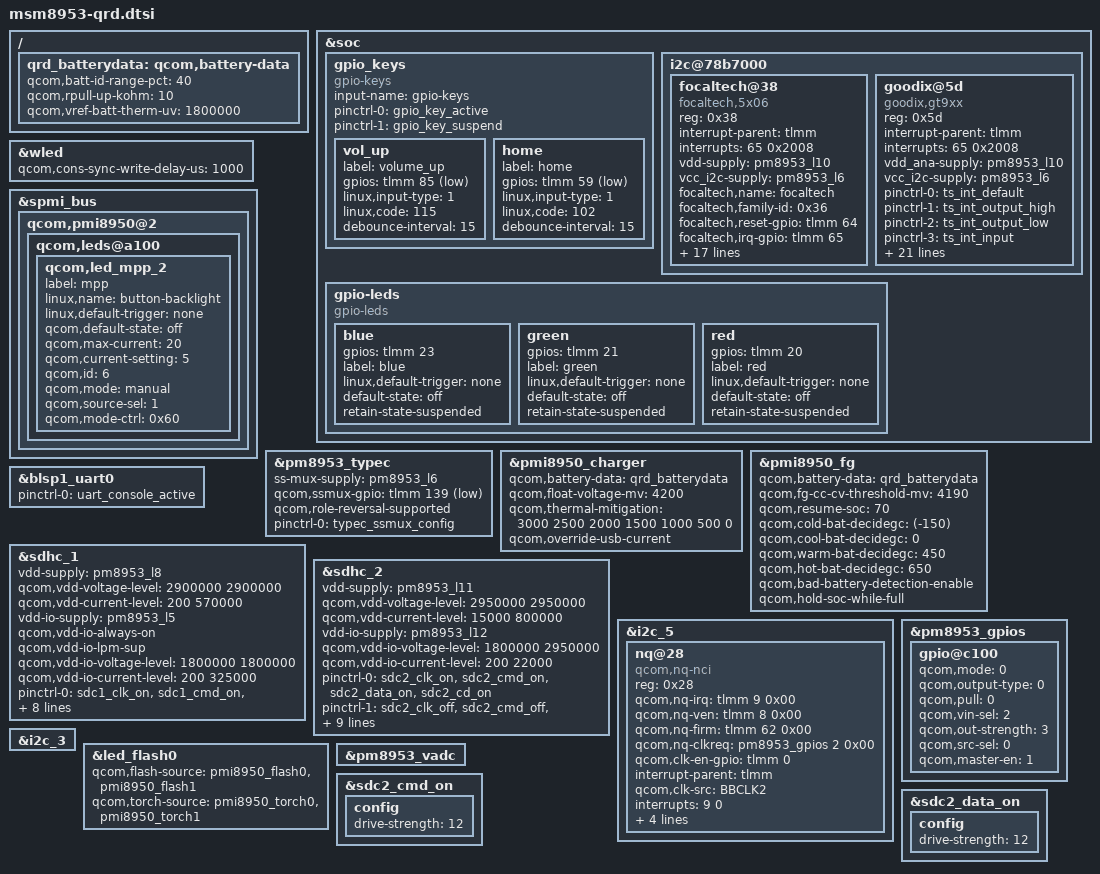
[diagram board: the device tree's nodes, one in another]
/*
 * Copyright (c) 2015-2016, The Linux Foundation. All rights reserved.
 *
 * This program is free software; you can redistribute it and/or modify
 * it under the terms of the GNU General Public License version 2 and
 * only version 2 as published by the Free Software Foundation.
 *
 * This program is distributed in the hope that it will be useful,
 * but WITHOUT ANY WARRANTY; without even the implied warranty of
 * MERCHANTABILITY or FITNESS FOR A PARTICULAR PURPOSE.  See the
 * GNU General Public License for more details.
 */

#include "msm8953-pinctrl.dtsi"
#include "msm8953-camera-sensor-qrd.dtsi"

&soc {
	gpio_keys {
		compatible = "gpio-keys";
		input-name = "gpio-keys";
		pinctrl-names = "tlmm_gpio_key_active","tlmm_gpio_key_suspend";
		pinctrl-0 = <&gpio_key_active>;
		pinctrl-1 = <&gpio_key_suspend>;

		vol_up {
			label = "volume_up";
			gpios = <&tlmm 85 0x1>;
			linux,input-type = <1>;
			linux,code = <115>;
			debounce-interval = <15>;
		};
		home {
			label = "home";
			gpios = <&tlmm 59 0x1>;
			linux,input-type = <1>;
			linux,code = <102>;
			debounce-interval = <15>;
		};
	};

	i2c@78b7000 { /* BLSP1 QUP3 */
		status = "okay";
		focaltech@38 {
			compatible = "focaltech,5x06";
			reg = <0x38>;
			interrupt-parent = <&tlmm>;
			interrupts = <65 0x2008>;
			vdd-supply = <&pm8953_l10>;
			vcc_i2c-supply = <&pm8953_l6>;
			/* pins used by touchscreen */
			focaltech,name = "focaltech";
			focaltech,family-id = <0x36>;
			focaltech,reset-gpio = <&tlmm 64 0x00>;
			focaltech,irq-gpio = <&tlmm 65 0x2008>;
			focaltech,display-coords = <0 0 800 1280>;
			focaltech,panel-coords = <0 0 800 1450>;
			focaltech,button-map= <139 102 158>;
			focaltech,no-force-update;
			focaltech,i2c-pull-up;
			focaltech,group-id = <1>;
			focaltech,hard-reset-delay-ms = <20>;
			focaltech,soft-reset-delay-ms = <200>;
			focaltech,num-max-touches = <5>;
			focaltech,fw-delay-aa-ms = <30>;
			focaltech,fw-delay-55-ms = <30>;
			focaltech,fw-upgrade-id1 = <0x79>;
			focaltech,fw-upgrade-id2 = <0x18>;
			focaltech,fw-delay-readid-ms = <10>;
			focaltech,fw-delay-era-flsh-ms = <2000>;
			focaltech,fw-auto-cal;
			focaltech,ignore-id-check;
		};
		goodix@5d {
			compatible = "goodix,gt9xx";
			reg = <0x5d>;
			interrupt-parent = <&tlmm>;
			interrupts = <65 0x2008>;
			vdd_ana-supply = <&pm8953_l10>;
			vcc_i2c-supply = <&pm8953_l6>;
			pinctrl-names = "default","int-output-high","int-output-low","int-input";
			pinctrl-0 = <&ts_int_default>;
			pinctrl-1 = <&ts_int_output_high>;
			pinctrl-2 = <&ts_int_output_low>;
			pinctrl-3 = <&ts_int_input>;
			reset-gpios = <&tlmm 64 0x00>;
			irq-gpios = <&tlmm 65 0x2008>;
			irq-flags = <2>;
			touchscreen-max-id = <11>;
			touchscreen-size-x = <800>;
			touchscreen-size-y = <1280>;
			touchscreen-max-w = <512>;
			touchscreen-max-p = <512>;
			touchscreen-key-map = <59>,<158>,<139>, <60>;
			goodix,slide-wakeup = <0>;
			goodix,type-a-report = <0>;
			goodix,driver-send-cfg = <0>;
			goodix,resume-in-workqueue = <0>;
			goodix,int-sync = <1>;
			goodix,swap-x2y = <0>;
			goodix,esd-protect = <1>;
			goodix,auto-update-cfg = <0>;
			goodix,power-off-sleep = <1>;	
			goodix,pen-suppress-finger = <0>;
			goodix,cfg-group0 = [00 20 03 00 05 0A 35 01 11 CF 28 0F 50 3C
			03 05 00 00 00 00 00 00 06 18 1A 1E 14 8C 2E 0E 55 57 D3 07 00
			00 00 02 02 1C 00 00 00 00 00 00 00 00 00 00 00 46 96 94 D5 02
			07 00 00 04 8B 4B 00 7D 58 00 72 66 00 69 77 00 62 8B 00 62 20
			18 10 08 F0 4A 3A FF FF 27 00 00 00 00 00 00 00 00 00 00 00 00
			00 00 00 00 00 00 00 00 00 00 00 00 00 00 02 04 06 08 0A 0C 0E
			10 12 14 16 18 1A 1C 00 00 00 00 00 00 00 00 00 00 00 00 00 00
			00 00 00 02 04 06 08 0A 0C 0F 10 12 13 14 18 1C 1D 1E 1F 20 21
			22 24 26 28 29 2A 16 00 00 00 00 00 00 00 00 00 00 00 00 00 00 00 00 08 01];
		};
	};
/* kun.chen rm
	vdd_vreg: vdd_vreg {
		compatible = "regulator-fixed";
		status = "ok";
		regulator-name = "vdd_vreg";
	};
*/
	gpio-leds {
		compatible = "gpio-leds";
		status = "okay";

		blue {
			gpios = <&tlmm 23 0x0>;
			label = "blue";
			linux,default-trigger = "none";
			default-state = "off";
			retain-state-suspended;
		};
		green {
			gpios = <&tlmm 21 0x0>;
			label = "green";
			linux,default-trigger = "none";
			default-state = "off";
			retain-state-suspended;
		};
		red {
			gpios = <&tlmm 20 0x0>;
			label = "red";
			linux,default-trigger = "none";
			default-state = "off";
			retain-state-suspended;
		};
	};
};

&wled {
	qcom,cons-sync-write-delay-us = <1000>;
};

&spmi_bus {
	qcom,pmi8950@2 {
		qcom,leds@a100 {
			status = "okay";
			qcom,led_mpp_2 {
				label = "mpp";
				linux,name = "button-backlight";
				linux,default-trigger = "none";
				qcom,default-state = "off";
				qcom,max-current = <20>;
				qcom,current-setting = <5>;
				qcom,id = <6>;
				qcom,mode = "manual";
				qcom,source-sel = <1>;
				qcom,mode-ctrl = <0x60>;
			};
		};
	};
};

/ {
	qrd_batterydata: qcom,battery-data {
		/*qcom,batt-id-range-pct = <15>;
		#include "batterydata-qrd-sku1-4v4-2800mah.dtsi"*/
		qcom,batt-id-range-pct = <40>;
		qcom,rpull-up-kohm = <10>;
		qcom,vref-batt-therm-uv = <1800000>;
		#include "batterydata-hwe30100100_2p-c801-4v2-6600mah_10k.dtsi"
		#include "batterydata-fullymax-fb382030xl-c801-4v2-135mah_20k.dtsi"
	};
};

&pm8953_typec {
	ss-mux-supply = <&pm8953_l6>;
	qcom,ssmux-gpio = <&tlmm 139 GPIO_ACTIVE_LOW>;
	qcom,role-reversal-supported;
	pinctrl-names = "default";
	pinctrl-0 = <&typec_ssmux_config>;
};

&pmi8950_charger {
	qcom,battery-data = <&qrd_batterydata>;
	qcom,float-voltage-mv = <4200>;
	/*qcom,chg-led-sw-controls;*/
	/*qcom,chg-led-support;*/
	/*qcom,external-typec;
	qcom,typec-psy-name = "typec";
	qcom,thermal-mitigation = <2650 2650 2650 2650 2600 700 0>;*/
	qcom,thermal-mitigation = <3000 2500 2000 1500 1000 500 0>;
	/*should be enabled after battery profile and charger testing*/
	qcom,override-usb-current;
	status = "okay";
};

&pmi8950_fg {
	qcom,battery-data = <&qrd_batterydata>;
	qcom,fg-cc-cv-threshold-mv = <4190>;
	qcom,resume-soc = <70>;
	qcom,cold-bat-decidegc = <(-150)>;
	qcom,cool-bat-decidegc = <0>;
	qcom,warm-bat-decidegc = <450>;
	qcom,hot-bat-decidegc = <650>;
	qcom,bad-battery-detection-enable;
	qcom,hold-soc-while-full;
};

&blsp1_uart0 {
	status = "ok";
	pinctrl-names = "default";
	pinctrl-0 = <&uart_console_active>;
};

&sdhc_1 {
	/* device core power supply */
	vdd-supply = <&pm8953_l8>;
	qcom,vdd-voltage-level = <2900000 2900000>;
	qcom,vdd-current-level = <200 570000>;

	/* device communication power supply */
	vdd-io-supply = <&pm8953_l5>;
	qcom,vdd-io-always-on;
	qcom,vdd-io-lpm-sup;
	qcom,vdd-io-voltage-level = <1800000 1800000>;
	qcom,vdd-io-current-level = <200 325000>;

	pinctrl-names = "active", "sleep";
	pinctrl-0 = <&sdc1_clk_on &sdc1_cmd_on &sdc1_data_on &sdc1_rclk_on>;
	pinctrl-1 = <&sdc1_clk_off &sdc1_cmd_off &sdc1_data_off &sdc1_rclk_off>;

	qcom,clk-rates = <400000 20000000 25000000 50000000 100000000 192000000
								384000000>;
	qcom,nonremovable;
	qcom,bus-speed-mode = "HS400_1p8v", "HS200_1p8v", "DDR_1p8v";

	status = "ok";
};

&sdhc_2 {
	/* device core power supply */
	vdd-supply = <&pm8953_l11>;
	qcom,vdd-voltage-level = <2950000 2950000>;
	qcom,vdd-current-level = <15000 800000>;

	/* device communication power supply */
	vdd-io-supply = <&pm8953_l12>;
	qcom,vdd-io-voltage-level = <1800000 2950000>;
	qcom,vdd-io-current-level = <200 22000>;

	pinctrl-names = "active", "sleep";
	pinctrl-0 = <&sdc2_clk_on &sdc2_cmd_on &sdc2_data_on &sdc2_cd_on>;
	pinctrl-1 = <&sdc2_clk_off &sdc2_cmd_off &sdc2_data_off &sdc2_cd_off>;

	#address-cells = <0>;
	interrupt-parent = <&sdhc_2>;
	interrupts = <0 1 2>;
	#interrupt-cells = <1>;
	interrupt-map-mask = <0xffffffff>;
	interrupt-map = <0 &intc 0 125 0
		1 &intc 0 221 0>;
	interrupt-names = "hc_irq", "pwr_irq", "status_irq";

	qcom,clk-rates = <400000 20000000 25000000 50000000 100000000
								200000000>;
	qcom,bus-speed-mode = "SDR12", "SDR25", "SDR50", "DDR50", "SDR104";

	status = "ok";
};

&i2c_5 { /* BLSP2 QUP1 (NFC) */
	nq@28 {
		    compatible = "qcom,nq-nci";
        	reg = <0x28>;
        	qcom,nq-irq = <&tlmm 9 0x00>;
        	qcom,nq-ven = <&tlmm 8 0x00>;
        	qcom,nq-firm = <&tlmm 62 0x00>;
        	qcom,nq-clkreq = <&pm8953_gpios 2 0x00>;
        	qcom,clk-en-gpio = <&tlmm 0 0x00>;
        	interrupt-parent = <&tlmm>;
        	qcom,clk-src = "BBCLK2";
        	interrupts = <9 0>;
        	interrupt-names = "nfc_irq";
        	pinctrl-names = "nfc_active", "nfc_suspend";
        	pinctrl-0 = <&nfc_int_active &nfc_disable_active>;
        	pinctrl-1 = <&nfc_int_suspend &nfc_disable_suspend>;
        	clocks = <&clock_gcc clk_bb_clk2_pin>;
        	clock-names = "ref_clk";
	};
};

&pm8953_gpios {
	/* GPIO 2 (NFC_CLK_REQ) */
	gpio@c100 {
		qcom,mode = <0>;
		qcom,output-type = <0>;
		qcom,pull = <0>;
		qcom,vin-sel = <2>;
		qcom,out-strength = <3>;
		qcom,src-sel = <0>;
		qcom,master-en = <1>;
		status = "okay";
	};
};

&i2c_3 {
	status = "ok";
};
/*
&flash_led {
	/delete-node/ qcom,flash_1;
	/delete-node/ qcom,torch_1;
};
*/
&led_flash0{
	qcom,flash-source = <&pmi8950_flash0 &pmi8950_flash1>;
	qcom,torch-source = <&pmi8950_torch0 &pmi8950_torch1>;
};

&pm8953_vadc {
	/delete-node/ chan@11;
};

&sdc2_cmd_on {
	config {
		drive-strength=<12>;
	};
};

&sdc2_data_on {
	config {
		drive-strength=<12>;
	};
};
